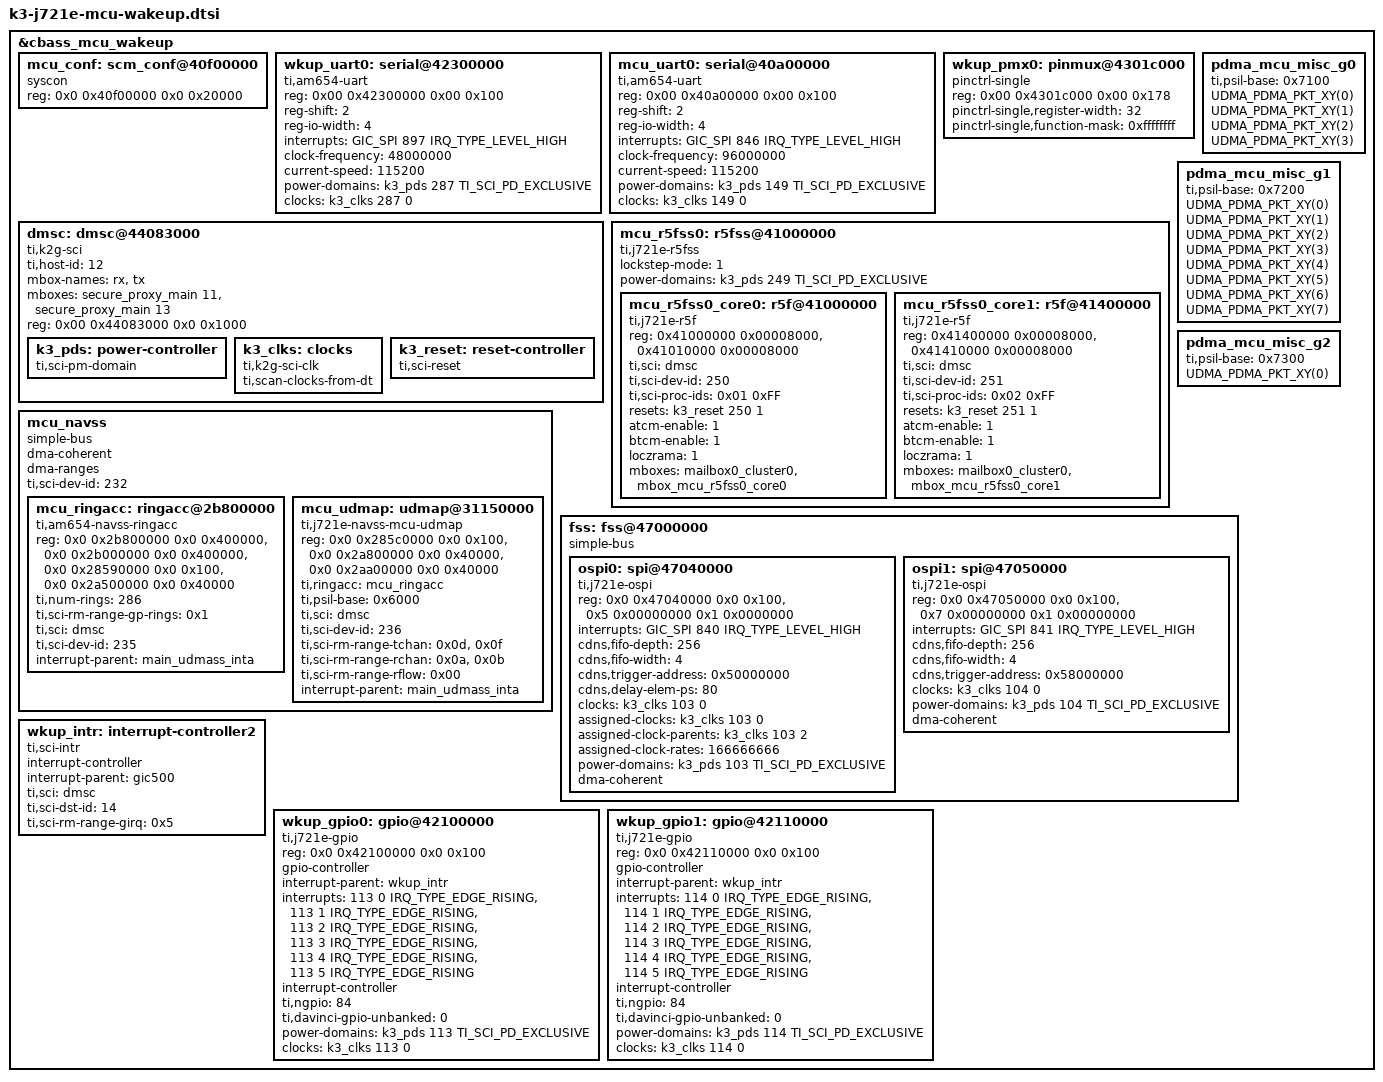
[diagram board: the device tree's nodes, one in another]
// SPDX-License-Identifier: GPL-2.0
/*
 * Device Tree Source for J721E SoC Family MCU/WAKEUP Domain peripherals
 *
 * Copyright (C) 2016-2019 Texas Instruments Incorporated - http://www.ti.com/
 */

&cbass_mcu_wakeup {
	mcu_conf: scm_conf@40f00000 {
		compatible = "syscon", "simple-mfd";
		reg = <0x0 0x40f00000 0x0 0x20000>;
		#address-cells = <1>;
		#size-cells = <1>;
		ranges = <0x0 0x0 0x40f00000 0x20000>;
	};

	wkup_uart0: serial@42300000 {
		compatible = "ti,am654-uart";
		reg = <0x00 0x42300000 0x00 0x100>;
		reg-shift = <2>;
		reg-io-width = <4>;
		interrupts = <GIC_SPI 897 IRQ_TYPE_LEVEL_HIGH>;
		clock-frequency = <48000000>;
		current-speed = <115200>;
		power-domains = <&k3_pds 287 TI_SCI_PD_EXCLUSIVE>;
		clocks = <&k3_clks 287 0>;
		clock-names = "fclk";
	};

	mcu_uart0: serial@40a00000 {
		compatible = "ti,am654-uart";
		reg = <0x00 0x40a00000 0x00 0x100>;
		reg-shift = <2>;
		reg-io-width = <4>;
		interrupts = <GIC_SPI 846 IRQ_TYPE_LEVEL_HIGH>;
		clock-frequency = <96000000>;
		current-speed = <115200>;
		power-domains = <&k3_pds 149 TI_SCI_PD_EXCLUSIVE>;
		clocks = <&k3_clks 149 0>;
		clock-names = "fclk";
	};

	wkup_pmx0: pinmux@4301c000 {
		compatible = "pinctrl-single";
		/* Proxy 0 addressing */
		reg = <0x00 0x4301c000 0x00 0x178>;
		#pinctrl-cells = <1>;
		pinctrl-single,register-width = <32>;
		pinctrl-single,function-mask = <0xffffffff>;
	};

	dmsc: dmsc@44083000 {
		compatible = "ti,k2g-sci";
		ti,host-id = <12>;

		mbox-names = "rx", "tx";

		mboxes= <&secure_proxy_main 11>,
			<&secure_proxy_main 13>;

		reg-names = "debug_messages";
		reg = <0x00 0x44083000 0x0 0x1000>;

		k3_pds: power-controller {
			compatible = "ti,sci-pm-domain";
			#power-domain-cells = <2>;
		};

		k3_clks: clocks {
			compatible = "ti,k2g-sci-clk";
			#clock-cells = <2>;
			ti,scan-clocks-from-dt;
		};

		k3_reset: reset-controller {
			compatible = "ti,sci-reset";
			#reset-cells = <2>;
		};
	};

	mcu_r5fss0: r5fss@41000000 {
		compatible = "ti,j721e-r5fss";
		lockstep-mode = <1>;
		#address-cells = <1>;
		#size-cells = <1>;
		ranges = <0x41000000 0x00 0x41000000 0x20000>,
			 <0x41400000 0x00 0x41400000 0x20000>;
		power-domains = <&k3_pds 249 TI_SCI_PD_EXCLUSIVE>;

		mcu_r5fss0_core0: r5f@41000000 {
			compatible = "ti,j721e-r5f";
			reg = <0x41000000 0x00008000>,
			      <0x41010000 0x00008000>;
			reg-names = "atcm", "btcm";
			ti,sci = <&dmsc>;
			ti,sci-dev-id = <250>;
			ti,sci-proc-ids = <0x01 0xFF>;
			resets = <&k3_reset 250 1>;
			atcm-enable = <1>;
			btcm-enable = <1>;
			loczrama = <1>;
			mboxes = <&mailbox0_cluster0 &mbox_mcu_r5fss0_core0>;
		};

		mcu_r5fss0_core1: r5f@41400000 {
			compatible = "ti,j721e-r5f";
			reg = <0x41400000 0x00008000>,
			      <0x41410000 0x00008000>;
			reg-names = "atcm", "btcm";
			ti,sci = <&dmsc>;
			ti,sci-dev-id = <251>;
			ti,sci-proc-ids = <0x02 0xFF>;
			resets = <&k3_reset 251 1>;
			atcm-enable = <1>;
			btcm-enable = <1>;
			loczrama = <1>;
			mboxes = <&mailbox0_cluster0 &mbox_mcu_r5fss0_core1>;
		};
	};

	mcu_navss: mcu_navss {
		compatible = "simple-bus";
		#address-cells = <2>;
		#size-cells = <2>;
		dma-coherent;
		dma-ranges;
		ranges;

		ti,sci-dev-id = <232>;

		mcu_ringacc: ringacc@2b800000 {
			compatible = "ti,am654-navss-ringacc";
			reg =	<0x0 0x2b800000 0x0 0x400000>,
				<0x0 0x2b000000 0x0 0x400000>,
				<0x0 0x28590000 0x0 0x100>,
				<0x0 0x2a500000 0x0 0x40000>;
			reg-names = "rt", "fifos", "proxy_gcfg", "proxy_target";
			ti,num-rings = <286>;
			ti,sci-rm-range-gp-rings = <0x1>; /* GP ring range */
			ti,sci = <&dmsc>;
			ti,sci-dev-id = <235>;
			interrupt-parent = <&main_udmass_inta>;
		};

		mcu_udmap: udmap@31150000 {
			compatible = "ti,j721e-navss-mcu-udmap";
			reg =	<0x0 0x285c0000 0x0 0x100>,
				<0x0 0x2a800000 0x0 0x40000>,
				<0x0 0x2aa00000 0x0 0x40000>;
			reg-names = "gcfg", "rchanrt", "tchanrt";
			#dma-cells = <3>;

			ti,ringacc = <&mcu_ringacc>;
			ti,psil-base = <0x6000>;

			ti,sci = <&dmsc>;
			ti,sci-dev-id = <236>;

			ti,sci-rm-range-tchan = <0x0d>, /* TX_CHAN */
						<0x0f>; /* TX_HCHAN */
			ti,sci-rm-range-rchan = <0x0a>, /* RX_CHAN */
						<0x0b>; /* RX_HCHAN */
			ti,sci-rm-range-rflow = <0x00>; /* GP RFLOW */

			interrupt-parent = <&main_udmass_inta>;
		};
	};

	pdma_mcu_misc_g0: pdma_mcu_misc_g0 {
		/* MCU_PDMA0 (MCU_PDMA_MISC_G0) */
		ti,psil-base = <0x7100>;

		/* ti,psil-config0-3 */
		UDMA_PDMA_PKT_XY(0);
		UDMA_PDMA_PKT_XY(1);
		UDMA_PDMA_PKT_XY(2);
		UDMA_PDMA_PKT_XY(3);
	};

	pdma_mcu_misc_g1: pdma_mcu_misc_g1 {
		/* MCU_PDMA1 (MCU_PDMA_MISC_G1) */
		ti,psil-base = <0x7200>;

		/* ti,psil-config0-7 */
		UDMA_PDMA_PKT_XY(0);
		UDMA_PDMA_PKT_XY(1);
		UDMA_PDMA_PKT_XY(2);
		UDMA_PDMA_PKT_XY(3);
		UDMA_PDMA_PKT_XY(4);
		UDMA_PDMA_PKT_XY(5);
		UDMA_PDMA_PKT_XY(6);
		UDMA_PDMA_PKT_XY(7);
	};

	pdma_mcu_misc_g2: pdma_mcu_misc_g2 {
		/* MCU_PDMA2 (MCU_PDMA_MISC_G2) */
		ti,psil-base = <0x7300>;

		/* ti,psil-config0 */
		UDMA_PDMA_PKT_XY(0);
	};

	fss: fss@47000000 {
		compatible = "simple-bus";
		#address-cells = <2>;
		#size-cells = <2>;
		ranges;

		ospi0: spi@47040000 {
			compatible = "ti,j721e-ospi", "ti,am654-ospi", "cdns,qspi-nor";
			reg = <0x0 0x47040000 0x0 0x100>,
				<0x5 0x00000000 0x1 0x0000000>;
			interrupts = <GIC_SPI 840 IRQ_TYPE_LEVEL_HIGH>;
			cdns,fifo-depth = <256>;
			cdns,fifo-width = <4>;
			cdns,trigger-address = <0x50000000>;
			cdns,delay-elem-ps = <80>;
			clocks = <&k3_clks 103 0>;
			assigned-clocks = <&k3_clks 103 0>;
			assigned-clock-parents = <&k3_clks 103 2>;
			assigned-clock-rates = <166666666>;
			power-domains = <&k3_pds 103 TI_SCI_PD_EXCLUSIVE>;
			#address-cells = <1>;
			#size-cells = <0>;
			dma-coherent;
		};

		ospi1: spi@47050000 {
			compatible = "ti,j721e-ospi", "ti,am654-ospi", "cdns,qspi-nor";
			reg = <0x0 0x47050000 0x0 0x100>,
				<0x7 0x00000000 0x1 0x00000000>;
			interrupts = <GIC_SPI 841 IRQ_TYPE_LEVEL_HIGH>;
			cdns,fifo-depth = <256>;
			cdns,fifo-width = <4>;
			cdns,trigger-address = <0x58000000>;
			clocks = <&k3_clks 104 0>;
			power-domains = <&k3_pds 104 TI_SCI_PD_EXCLUSIVE>;
			#address-cells = <1>;
			#size-cells = <0>;
			dma-coherent;
		};
	};

	wkup_intr: interrupt-controller2 {
		compatible = "ti,sci-intr";
		interrupt-controller;
		interrupt-parent = <&gic500>;
		#interrupt-cells = <3>;
		ti,sci = <&dmsc>;
		ti,sci-dst-id = <14>;
		ti,sci-rm-range-girq = <0x5>;
	};

	wkup_gpio0: gpio@42100000 {
		compatible = "ti,j721e-gpio", "ti,keystone-gpio";
		reg = <0x0 0x42100000 0x0 0x100>;
		gpio-controller;
		#gpio-cells = <2>;
		interrupt-parent = <&wkup_intr>;
		interrupts = <113 0 IRQ_TYPE_EDGE_RISING>,
			     <113 1 IRQ_TYPE_EDGE_RISING>,
			     <113 2 IRQ_TYPE_EDGE_RISING>,
			     <113 3 IRQ_TYPE_EDGE_RISING>,
			     <113 4 IRQ_TYPE_EDGE_RISING>,
			     <113 5 IRQ_TYPE_EDGE_RISING>;
		interrupt-controller;
		#interrupt-cells = <2>;
		ti,ngpio = <84>;
		ti,davinci-gpio-unbanked = <0>;
		power-domains = <&k3_pds 113 TI_SCI_PD_EXCLUSIVE>;
		clocks = <&k3_clks 113 0>;
		clock-names = "gpio";
	};

	wkup_gpio1: gpio@42110000 {
		compatible = "ti,j721e-gpio", "ti,keystone-gpio";
		reg = <0x0 0x42110000 0x0 0x100>;
		gpio-controller;
		#gpio-cells = <2>;
		interrupt-parent = <&wkup_intr>;
		interrupts = <114 0 IRQ_TYPE_EDGE_RISING>,
			     <114 1 IRQ_TYPE_EDGE_RISING>,
			     <114 2 IRQ_TYPE_EDGE_RISING>,
			     <114 3 IRQ_TYPE_EDGE_RISING>,
			     <114 4 IRQ_TYPE_EDGE_RISING>,
			     <114 5 IRQ_TYPE_EDGE_RISING>;
		interrupt-controller;
		#interrupt-cells = <2>;
		ti,ngpio = <84>;
		ti,davinci-gpio-unbanked = <0>;
		power-domains = <&k3_pds 114 TI_SCI_PD_EXCLUSIVE>;
		clocks = <&k3_clks 114 0>;
		clock-names = "gpio";
	};
};
